# AE612FA0E5597LS0_CM55_HP_View register map
Vendor: Alif Semiconductor; Series: E6; File version: 1.0
CPU: CM55 r1p0, selectable endian, MPU, FPU, double-precision FPU, DSP, VTOR, 8 interrupt priority bits, 1 SAU regions
Registers are 32-bit, read-write, reset 0x0 unless marked. A register's access mark holds for its fields unless they carry their own. Offsets are from the block's base; [hi:lo] are bit positions; {n}, {i} and the like mark numbered series; 'fields as' and 'values as' point back to an identical list.

## CLKCTL_SYS
Base 0x1A010000
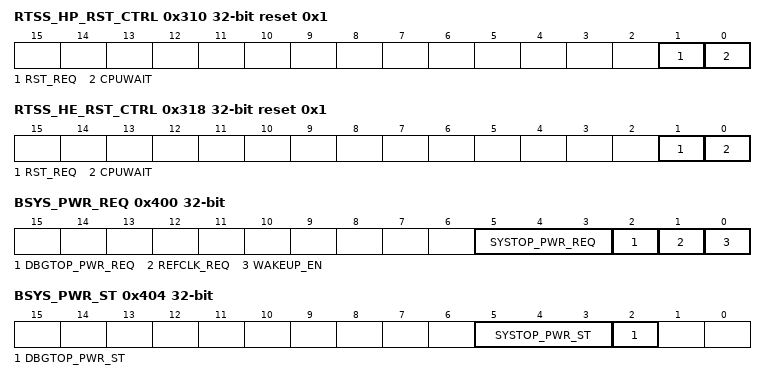
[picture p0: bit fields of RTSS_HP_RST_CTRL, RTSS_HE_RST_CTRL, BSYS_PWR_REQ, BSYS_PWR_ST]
0x310 RTSS_HP_RST_CTRL reset 0x1 — RTSS-HP Reset Control Register
  [1] RST_REQ — Reset request for RTSS-HP.
    0=No reset requested; 1=Reset requested
  [0] CPUWAIT — CPU wait control. When CPUWAIT becomes 0x0, any attempt to revert back to 0x1 is ignored. This field only returns to 0x1 when any of the following occurs: - External power-on reset - Internal power-on reset - Debug reset - APSS reset - RTSS-HP reset This field becomes read-only when the associated CPUWAIT_WEN is 0x0. Any attempt to set this field to 0x0 by software is ignored.
    0=CPUWAIT signal of RTSS-HP is deasserted; 1=CPUWAIT signal of RTSS-HP is asserted
0x314 RTSS_HP_RST_ST ro — RTSS-HP Reset Status Register
  [2:1] RST_ACK — Status of reset request.
    0=No reset requested; 1=Reset request unable to complete; 2=Reset request complete
0x318 RTSS_HE_RST_CTRL reset 0x1 — RTSS-HE Reset Control Register
  [1] RST_REQ — Reset request for RTSS-HE.
    0=No reset requested; 1=Reset requested
  [0] CPUWAIT — CPU wait control. When CPUWAIT becomes 0x0, any attempt to revert back to 0x1 is ignored. This field only returns to 0x1 when any of the following occurs: - External power-on reset - Internal power-on reset - Debug reset - APSS reset - RTSS-HE reset This field becomes read-only when the associated CPUWAIT_WEN is 0x0. Any attempt to set this field to 0x0 by software is ignored.
    0=CPUWAIT signal of RTSS-HE is deasserted; 1=CPUWAIT signal of RTSS-HE is asserted
0x31C RTSS_HE_RST_ST ro — RTSS-HE Reset Status Register
  fields as RTSS_HP_RST_ST
0x400 BSYS_PWR_REQ — Base System Power Request Register
  [5:3] SYSTOP_PWR_REQ — Selects SYSTOP power domain behavior when no activity in the domain.
    0=No request for logic or volatile memory to be powered; 1=No request for logic to be powered, but volatile memory must be retained; 2=Request for logic to be powered, but volatile memory can be either powered or retained; 3=Request for logic to be powered, but volatile memory can be either powered or retained; {v}=Request for logic and volatile memory to be powered (v=4..7)
  [2] DBGTOP_PWR_REQ — Selects DBGTOP power domain behavior when no activity in the domain.
    0=No request for DBGTOP to be powered; 1=Request for DBGTOP to be powered
  [1] REFCLK_REQ — Request SYST_REFCLK.
    0=No request for SYST_REFCLK to be supplied; 1=Request for SYST_REFCLK to be supplied
  [0] WAKEUP_EN — APSS wakeup enable.
    0=Wakeup for APSS is disabled; 1=Wakeup for APSS is enabled
0x404 BSYS_PWR_ST ro (reset mask 0xFFFFFFC3) — Base System Power Status Register
  [5:3] SYSTOP_PWR_ST — SYSTOP power domain status. All other values are reserved.
    0=SYSTOP is in the OFF or WARM_RST power mode; 1=SYSTOP is in the MEM_RET power mode; 2=SYSTOP is in the FUNC_RET power mode; 4=SYSTOP is in the ON power mode
  [2] DBGTOP_PWR_ST — DBGTOP power domain status.
    0=DBGTOP is in the OFF or WARM_RST power mode; 1=DBGTOP is in the ON power mode
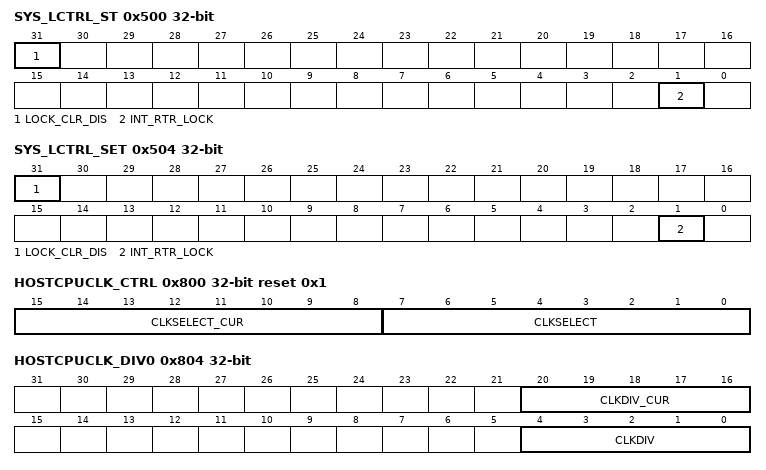
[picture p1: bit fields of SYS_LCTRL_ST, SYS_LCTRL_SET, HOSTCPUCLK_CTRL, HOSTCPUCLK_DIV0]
0x500 SYS_LCTRL_ST ro — System Lock Control Status Register
  [31] LOCK_CLR_DIS — SYS_LCTRL_CLR register behavior indicator
    0=Writes to the SYS_LCTRL_CLR register take effect; 1=Writes to the SYS_LCTRL_CLR register are ignored
  [1] INT_RTR_LOCK — IRQRTR lockdown interface indicator
    0=IRQRTR lockdown interface is de-asserted; 1=IRQRTR lockdown interface is asserted
0x504 SYS_LCTRL_SET — System Lock Control Set Register
  [31] LOCK_CLR_DIS wo — Writing 0x1 to this bit sets the SYS_LCTRL_ST[LOCK_CLR_DIS] bit to 0x1. Writing 0x0 to this bit has no effect on the value of the SYS_LCTRL_ST[LOCK_CLR_DIS] bit. This bit always reads as 0x0.
  [1] INT_RTR_LOCK wo — Writing 0x1 to this bit sets the SYS_LCTRL_ST[INT_RTR_LOCK] bit to 0x1. Writing 0x0 to this bit has no effect on the value of the SYS_LCTRL_ST[INT_RTR_LOCK] bit. This bit always reads as 0x0.
0x508 SYS_LCTRL_CLR — System Lock Control Clear Register
  [1] INT_RTR_LOCK wo — Writing 0x1 to this bit sets the SYS_LCTRL_ST[INT_RTR_LOCK] bit to 0x0. Writing 0x0 to this bit has no effect on the value of the SYS_LCTRL_ST[INT_RTR_LOCK] bit. This bit always reads as 0x0.
0x800 HOSTCPUCLK_CTRL reset 0x1 (reset mask 0xFFFF00FF) — APSS_CLK Clock Control Register
  [15:8] CLKSELECT_CUR ro — Currently selected clock source for APSS_CLK All other values are reserved.
    0=Clock gated; 1=SYST_REFCLK; 2=SYSPLL_CLK divided by HOSTCPUCLK_DIV1[CLKDIV]; 4=CPUPLL_CLK divided by HOSTCPUCLK_DIV0[CLKDIV]
  [7:0] CLKSELECT — Select the clock source for APSS_CLK All other values are reserved. Selecting a reserved value can cause a deadlock.
    values as CLKSELECT_CUR
0x804 HOSTCPUCLK_DIV0 (reset mask 0xFFE0FFFF) — APSS_CLK Clock Divider 0 Register
  [20:16] CLKDIV_CUR ro — Current value of integer divider applied to SYSPLL_CLK
    0=Divided by 1; 1=Divided by 2; 31=Divided by 32
  [4:0] CLKDIV — Select the value of the integer divider applied to SYSPLL_CLK
    0=Divide by 1; 1=Divide by 2; 31=Divide by 32
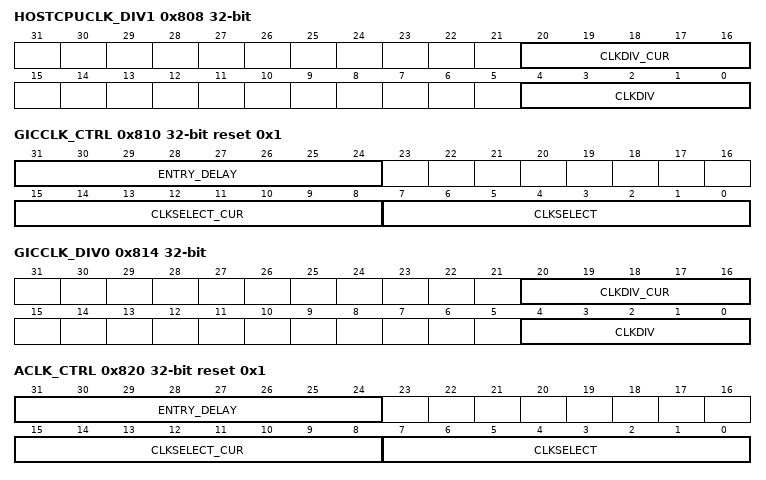
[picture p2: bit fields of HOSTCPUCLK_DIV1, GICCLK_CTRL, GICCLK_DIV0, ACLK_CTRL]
0x808 HOSTCPUCLK_DIV1 (reset mask 0xFFE0FFFF) — APSS_CLK Clock Divider 1 Register
  [20:16] CLKDIV_CUR ro — Current value of integer divider applied to CPUPLL_CLK
    0=Divided by 1; 1=Divided by 2; 31=Divided by 32
  [4:0] CLKDIV — Select the value of the integer divider applied to CPUPLL_CLK
    0=Divide by 1; 1=Divide by 2; 31=Divide by 32
0x810 GICCLK_CTRL reset 0x1 (reset mask 0xFFFF00FF) — GICCLK Control Register
  [31:24] ENTRY_DELAY — Configure number of idle clock cycles before clock is gated
  [15:8] CLKSELECT_CUR ro — Currently selected clock source for GICCLK. All other values are reserved.
    0=Clock gate; 1=SYST_REFCLK; 2=SYSPLL_CLK
  [7:0] CLKSELECT — Select the clock source for GICCLK. All other values are reserved. Selecting a reserved value can cause a deadlock.
    0=Clock gate; 1=SYST_REFCLK; 2=SYSPLL_CLK
0x814 GICCLK_DIV0 (reset mask 0xFFE0FFFF) — GICCLK Divider 0 Register
  [20:16] CLKDIV_CUR ro — Current value of integer divider applied to SYSPLL_CLK.
    0=Divide by 1; 1=Divide by 2; 31=Divide by 32
  [4:0] CLKDIV — Select the value of the integer divider applied to SYSPLL_CLK.
    0=Divide by 1; 1=Divide by 2; 31=Divide by 32
0x820 ACLK_CTRL reset 0x1 (reset mask 0xFFFF00FF) — SYST_ACLK Clock Control Register
  [31:24] ENTRY_DELAY — Configure number of idle clock cycles before clock is gated.
  [15:8] CLKSELECT_CUR ro — Currently selected clock source for SYST_ACLK. All other values are reserved.
    0=Clock gated; 1=SYST_REFCLK; 2=SYSPLL_CLK divided by ACLK_DIV0[CLKDIV]
  [7:0] CLKSELECT — Select the clock source for SYST_ACLK. All other values are reserved. Selecting a reserved value can cause a deadlock.
    values as CLKSELECT_CUR
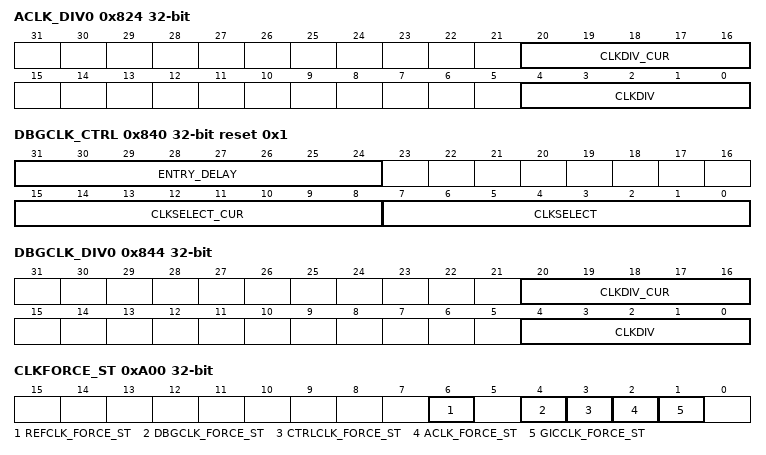
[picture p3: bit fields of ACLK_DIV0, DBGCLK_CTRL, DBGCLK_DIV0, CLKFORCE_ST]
0x824 ACLK_DIV0 (reset mask 0xFFE0FFFF) — SYST_ACLK Clock Divider 0 Register
  [20:16] CLKDIV_CUR ro — Current value of integer divider applied to SYSPLL_CLK.
    0=Divided by 1; 1=Divided by 2; 31=Divided by 32
  [4:0] CLKDIV — Select the value of the integer divider applied to SYSPLL_CLK.
    0=Divide by 1; 1=Divide by 2; 31=Divide by 32
0x840 DBGCLK_CTRL reset 0x1 (reset mask 0xFFFF00FF) — DBGCLK Clock Control Register
  [31:24] ENTRY_DELAY — Configure number of idle clock cycles before clock is gated
  [15:8] CLKSELECT_CUR ro — Currently selected clock source for DBGCLK. All other values are reserved.
    0=Clock gate; 1=SYST_REFCLK; 2=SYSPLL_CLK
  [7:0] CLKSELECT — Select the clock source for DBGCLK. All other values are reserved. Selecting a reserved value can cause a deadlock.
    0=Clock gate; 1=SYST_REFCLK; 2=SYSPLL_CLK
0x844 DBGCLK_DIV0 (reset mask 0xFFE0FFFF) — DBGCLK Clock Divider 0 Register
  fields as GICCLK_DIV0
0xA00 CLKFORCE_ST ro — Clock Force Status Register
  [all] fields
    0=High-level clock gating is enabled; 1=High-level clock gating is disabled
  [6] REFCLK_FORCE_ST — Status of SYST_REFCLK clock force.
  [4] DBGCLK_FORCE_ST — Status of DBGCLK clock force.
  [3] CTRLCLK_FORCE_ST — Status of CTRLCLK clock force.
  [2] ACLK_FORCE_ST — Status of SYST_ACLK clock force.
  [1] GICCLK_FORCE_ST — Status of GICCLK clock force.
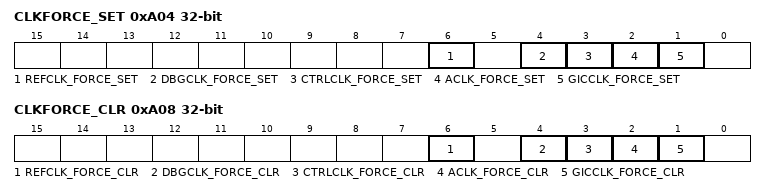
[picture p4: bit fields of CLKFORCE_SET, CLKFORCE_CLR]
0xA04 CLKFORCE_SET — Clock Force Set Register
  [6] REFCLK_FORCE_SET wo — Set CLKFORCE_ST[REFCLK_FORCE_ST] bit. Writing 0x0 has no effect. This field always reads as 0x0.
  [4] DBGCLK_FORCE_SET wo — Set CLKFORCE_ST[DBGCLK_FORCE_ST] bit. Writing 0x0 has no effect. This field always reads as 0x0.
  [3] CTRLCLK_FORCE_SET wo — Set CLKFORCE_ST[CTRLCLK_FORCE_ST] bit. Writing 0x0 has no effect. This field always reads as 0x0.
  [2] ACLK_FORCE_SET wo — Set CLKFORCE_ST[ACLK_FORCE_ST] bit. Writing 0x0 has no effect. This field always reads as 0x0.
  [1] GICCLK_FORCE_SET wo — Set CLKFORCE_ST[GICCLK_FORCE_ST] bit. Writing 0x0 has no effect. This field always reads as 0x0.
0xA08 CLKFORCE_CLR — Clock Force Clear Register
  [6] REFCLK_FORCE_CLR wo — Clear CLKFORCE_ST[REFCLK_FORCE_ST] bit. Writing 0x0 has no effect. This field always reads as 0x0.
  [4] DBGCLK_FORCE_CLR wo — Clear CLKFORCE_ST[DBGCLK_FORCE_ST] bit. Writing 0x0 has no effect. This field always reads as 0x0.
  [3] CTRLCLK_FORCE_CLR wo — Clear CLKFORCE_ST[CTRLCLK_FORCE_ST] bit. Writing 0x0 has no effect. This field always reads as 0x0.
  [2] ACLK_FORCE_CLR wo — Clear CLKFORCE_ST[ACLK_FORCE_ST] bit. Writing 0x0 has no effect. This field always reads as 0x0.
  [1] GICCLK_FORCE_CLR wo — Clear CLKFORCE_ST[GICCLK_FORCE_ST] bit. Writing 0x0 has no effect. This field always reads as 0x0.
